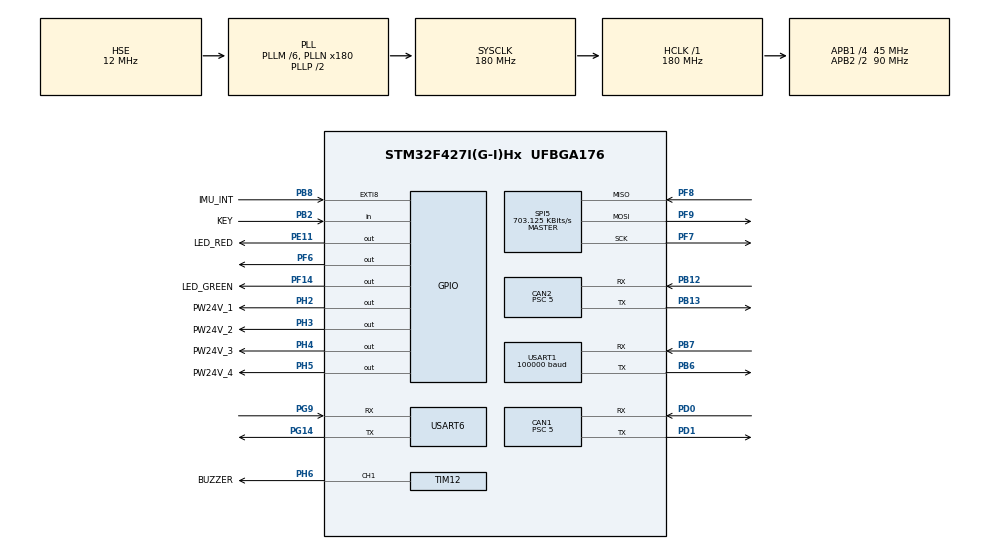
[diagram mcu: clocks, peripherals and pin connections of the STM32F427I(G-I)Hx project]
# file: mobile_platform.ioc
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CAN1.ABOM=ENABLE
CAN1.BS1=CAN_BS1_3TQ
CAN1.BS2=CAN_BS2_5TQ
CAN1.CalculateTimeQuantum=111.11111111111111
CAN1.Prescaler=5
CAN1.TXFP=DISABLE
CAN2.ABOM=ENABLE
CAN2.BS1=CAN_BS1_3TQ
CAN2.BS2=CAN_BS2_5TQ
CAN2.CalculateTimeQuantum=111.11111111111111
CAN2.Prescaler=5
CAN2.TXFP=DISABLE
Dma.Request0=USART1_RX
Dma.USART1_RX.0.Direction=DMA_PERIPH_TO_MEMORY
Dma.USART1_RX.0.FIFOMode=DMA_FIFOMODE_DISABLE
Dma.USART1_RX.0.Instance=DMA2_Stream2
Dma.USART1_RX.0.MemDataAlignment=DMA_MDATAALIGN_BYTE
Dma.USART1_RX.0.MemInc=DMA_MINC_ENABLE
Dma.USART1_RX.0.Mode=DMA_CIRCULAR
Dma.USART1_RX.0.PeriphDataAlignment=DMA_PDATAALIGN_BYTE
Dma.USART1_RX.0.PeriphInc=DMA_PINC_DISABLE
Dma.USART1_RX.0.Priority=DMA_PRIORITY_LOW
FREERTOS.BinarySemaphores01=myBinarySem01,Dynamic,NULL
FREERTOS.INCLUDE_vTaskDelayUntil=1
FREERTOS.Tasks01=defaultTask,0,128,StartDefaultTask,Default,NULL
Mcu.Family=STM32F4
Mcu.Name=STM32F427I(G-I)Hx
Mcu.Package=UFBGA176
NVIC.CAN1_RX0_IRQn=true\:5\:0\:false\:false\:true\:true\:true
NVIC.CAN1_TX_IRQn=true\:5\:0\:false\:false\:true\:true\:true
NVIC.CAN2_RX1_IRQn=true\:5\:0\:false\:false\:true\:true\:true
NVIC.CAN2_TX_IRQn=true\:5\:0\:false\:false\:true\:true\:true
NVIC.DMA2_Stream2_IRQn=true\:5\:0\:false\:false\:true\:true\:false
NVIC.EXTI9_5_IRQn=true\:5\:0\:false\:false\:true\:true\:true
NVIC.PriorityGroup=NVIC_PRIORITYGROUP_4
NVIC.SPI5_IRQn=true\:5\:0\:false\:false\:true\:true\:true
NVIC.USART1_IRQn=true\:5\:0\:false\:false\:true\:true\:true
NVIC.USART6_IRQn=true\:5\:0\:false\:false\:true\:true\:true
PA13.Mode=Serial_Wire
PA13.Signal=SYS_JTMS-SWDIO
PA14.Mode=Serial_Wire
PA14.Signal=SYS_JTCK-SWCLK
PB12.Mode=Slave
PB12.Signal=CAN2_RX
PB13.Mode=Slave
PB13.Signal=CAN2_TX
PB2/BOOT1.GPIO_Label=KEY
PB2/BOOT1.Signal=GPIO_Input
PB6.Mode=Asynchronous
PB6.Signal=USART1_TX
PB7.Mode=Asynchronous
PB7.Signal=USART1_RX
PB8.GPIO_Label=IMU_INT
PB8.Signal=GPXTI8
PD0.Mode=Master
PD0.Signal=CAN1_RX
PD1.Mode=Master
PD1.Signal=CAN1_TX
PE11.GPIO_Label=LED_RED
PE11.Signal=GPIO_Output
PF14.GPIO_Label=LED_GREEN
PF14.Signal=GPIO_Output
PF6.Signal=GPIO_Output
PF7.Mode=Full_Duplex_Master
PF7.Signal=SPI5_SCK
PF8.Mode=Full_Duplex_Master
PF8.Signal=SPI5_MISO
PF9.Mode=Full_Duplex_Master
PF9.Signal=SPI5_MOSI
PG14.Mode=Asynchronous
PG14.Signal=USART6_TX
PG9.Mode=Asynchronous
PG9.Signal=USART6_RX
PH0/OSC_IN.Mode=HSE-External-Oscillator
PH0/OSC_IN.Signal=RCC_OSC_IN
PH1/OSC_OUT.Mode=HSE-External-Oscillator
PH1/OSC_OUT.Signal=RCC_OSC_OUT
PH2.GPIO_Label=PW24V_1
PH2.Signal=GPIO_Output
PH3.GPIO_Label=PW24V_2
PH3.Signal=GPIO_Output
PH4.GPIO_Label=PW24V_3
PH4.Signal=GPIO_Output
PH5.GPIO_Label=PW24V_4
PH5.Signal=GPIO_Output
PH6.GPIO_Label=BUZZER
PH6.Signal=S_TIM12_CH1
ProjectManager.HeapSize=0x500
ProjectManager.StackSize=0x1000
ProjectManager.TargetToolchain=MDK-ARM V5
RCC.48MHZClocksFreq_Value=90000000
RCC.AHBFreq_Value=180000000
RCC.APB1CLKDivider=RCC_HCLK_DIV4
RCC.APB1Freq_Value=45000000
RCC.APB1TimFreq_Value=90000000
RCC.APB2CLKDivider=RCC_HCLK_DIV2
RCC.APB2Freq_Value=90000000
RCC.APB2TimFreq_Value=180000000
RCC.CortexFreq_Value=180000000
RCC.HCLKFreq_Value=180000000
RCC.HSE_VALUE=12000000
RCC.HSI_VALUE=16000000
RCC.LSE_VALUE=32768
RCC.PLLM=6
RCC.PLLN=180
RCC.PLLSourceVirtual=RCC_PLLSOURCE_HSE
RCC.SYSCLKFreq_VALUE=180000000
RCC.SYSCLKSource=RCC_SYSCLKSOURCE_PLLCLK
RCC.VCOOutputFreq_Value=360000000
SH.S_TIM12_CH1.0=TIM12_CH1,PWM Generation1 CH1
SPI5.BaudRatePrescaler=SPI_BAUDRATEPRESCALER_128
SPI5.CalculateBaudRate=703.125 KBits/s
SPI5.Direction=SPI_DIRECTION_2LINES
SPI5.Mode=SPI_MODE_MASTER
SPI5.VirtualType=VM_MASTER
TIM12.Channel-PWM\ Generation1\ CH1=TIM_CHANNEL_1
USART1.BaudRate=100000
USART1.Parity=PARITY_EVEN
USART1.VirtualMode=VM_ASYNC
USART6.VirtualMode=VM_ASYNC
VP_FREERTOS_VS_ENABLE.Mode=Enabled
board=custom

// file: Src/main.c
/**
  ******************************************************************************
  * @file           : main.c
  * @brief          : Main program body
  ******************************************************************************
  * This notice applies to any and all portions of this file
  * that are not between comment pairs USER CODE BEGIN and
  * USER CODE END. Other portions of this file, whether
  * inserted by the user or by software development tools
  * are owned by their respective copyright owners.
  *
  * Copyright (c) 2018 STMicroelectronics International N.V.
  * All rights reserved.
  *
  * Redistribution and use in source and binary forms, with or without
  * modification, are permitted, provided that the following conditions are met:
  *
  * 1. Redistribution of source code must retain the above copyright notice,
  *    this list of conditions and the following disclaimer.
  * 2. Redistributions in binary form must reproduce the above copyright notice,
  *    this list of conditions and the following disclaimer in the documentation
  *    and/or other materials provided with the distribution.
  * 3. Neither the name of STMicroelectronics nor the names of other
  *    contributors to this software may be used to endorse or promote products
  *    derived from this software without specific written permission.
  * 4. This software, including modifications and/or derivative works of this
  *    software, must execute solely and exclusively on microcontroller or
  *    microprocessor devices manufactured by or for STMicroelectronics.
  * 5. Redistribution and use of this software other than as permitted under
  *    this license is void and will automatically terminate your rights under
  *    this license.
  *
  * THIS SOFTWARE IS PROVIDED BY STMICROELECTRONICS AND CONTRIBUTORS "AS IS"
  * AND ANY EXPRESS, IMPLIED OR STATUTORY WARRANTIES, INCLUDING, BUT NOT
  * LIMITED TO, THE IMPLIED WARRANTIES OF MERCHANTABILITY, FITNESS FOR A
  * PARTICULAR PURPOSE AND NON-INFRINGEMENT OF THIRD PARTY INTELLECTUAL PROPERTY
  * RIGHTS ARE DISCLAIMED TO THE FULLEST EXTENT PERMITTED BY LAW. IN NO EVENT
  * SHALL STMICROELECTRONICS OR CONTRIBUTORS BE LIABLE FOR ANY DIRECT, INDIRECT,
  * INCIDENTAL, SPECIAL, EXEMPLARY, OR CONSEQUENTIAL DAMAGES (INCLUDING, BUT NOT
  * LIMITED TO, PROCUREMENT OF SUBSTITUTE GOODS OR SERVICES; LOSS OF USE, DATA,
  * OR PROFITS; OR BUSINESS INTERRUPTION) HOWEVER CAUSED AND ON ANY THEORY OF
  * LIABILITY, WHETHER IN CONTRACT, STRICT LIABILITY, OR TORT (INCLUDING
  * NEGLIGENCE OR OTHERWISE) ARISING IN ANY WAY OUT OF THE USE OF THIS SOFTWARE,
  * EVEN IF ADVISED OF THE POSSIBILITY OF SUCH DAMAGE.
  *
  ******************************************************************************
  */
#include "main.h"
#include "stm32f4xx_hal.h"
#include "cmsis_os.h"
#include "can.h"
#include "dma.h"
#include "spi.h"
#include "tim.h"
#include "usart.h"
#include "gpio.h"

/* USER CODE BEGIN Includes */
#include "sys_config.h"
/* USER CODE END Includes */

/* USER CODE BEGIN PV */
/* Private variables ---------------------------------------------------------*/

/* USER CODE END PV */

void SystemClock_Config(void);
void MX_FREERTOS_Init(void);

/* USER CODE BEGIN PFP */
/* Private function prototypes -----------------------------------------------*/

/* USER CODE END PFP */

int main(void)
{

  /* MCU Configuration----------------------------------------------------------*/

  /* Reset of all peripherals, Initializes the Flash interface and the Systick. */
  HAL_Init();

  /* Configure the system clock */
  SystemClock_Config();

  /* Initialize all configured peripherals */
  MX_GPIO_Init();
  MX_DMA_Init();
  MX_USART1_UART_Init();
  MX_USART6_UART_Init();
  MX_CAN1_Init();
  MX_CAN2_Init();
  MX_TIM12_Init();
  MX_SPI5_Init();
  /* USER CODE BEGIN 2 */
//  delay_init(180);
	HAL_TIM_PWM_Start(&htim12,TIM_CHANNEL_1);
	led_off();
	dbus_uart_init();
	can_filter_init(&hcan1);
	can_filter_init(&hcan2);
  /* USER CODE END 2 */

  /* Call init function for freertos objects (in freertos.c) */
  MX_FREERTOS_Init();

  /* Start scheduler */
  osKernelStart();

  /* We should never get here as control is now taken by the scheduler */

  /* Infinite loop */
  while (1)
  {

  }

}

void SystemClock_Config(void)
{

  RCC_OscInitTypeDef RCC_OscInitStruct;
  RCC_ClkInitTypeDef RCC_ClkInitStruct;

    /**Configure the main internal regulator output voltage
    */
  __HAL_RCC_PWR_CLK_ENABLE();

  __HAL_PWR_VOLTAGESCALING_CONFIG(PWR_REGULATOR_VOLTAGE_SCALE1);

    /**Initializes the CPU, AHB and APB busses clocks
    */
  RCC_OscInitStruct.OscillatorType = RCC_OSCILLATORTYPE_HSE;
  RCC_OscInitStruct.HSEState = RCC_HSE_ON;
  RCC_OscInitStruct.PLL.PLLState = RCC_PLL_ON;
  RCC_OscInitStruct.PLL.PLLSource = RCC_PLLSOURCE_HSE;
  RCC_OscInitStruct.PLL.PLLM = 6;
  RCC_OscInitStruct.PLL.PLLN = 180;
  RCC_OscInitStruct.PLL.PLLP = RCC_PLLP_DIV2;
  RCC_OscInitStruct.PLL.PLLQ = 4;
  if (HAL_RCC_OscConfig(&RCC_OscInitStruct) != HAL_OK)
  {
    _Error_Handler(__FILE__, __LINE__);
  }

    /**Activate the Over-Drive mode
    */
  if (HAL_PWREx_EnableOverDrive() != HAL_OK)
  {
    _Error_Handler(__FILE__, __LINE__);
  }

    /**Initializes the CPU, AHB and APB busses clocks
    */
  RCC_ClkInitStruct.ClockType = RCC_CLOCKTYPE_HCLK|RCC_CLOCKTYPE_SYSCLK
                              |RCC_CLOCKTYPE_PCLK1|RCC_CLOCKTYPE_PCLK2;
  RCC_ClkInitStruct.SYSCLKSource = RCC_SYSCLKSOURCE_PLLCLK;
  RCC_ClkInitStruct.AHBCLKDivider = RCC_SYSCLK_DIV1;
  RCC_ClkInitStruct.APB1CLKDivider = RCC_HCLK_DIV4;
  RCC_ClkInitStruct.APB2CLKDivider = RCC_HCLK_DIV2;

  if (HAL_RCC_ClockConfig(&RCC_ClkInitStruct, FLASH_LATENCY_5) != HAL_OK)
  {
    _Error_Handler(__FILE__, __LINE__);
  }

    /**Configure the Systick interrupt time
    */
  HAL_SYSTICK_Config(HAL_RCC_GetHCLKFreq()/1000);

    /**Configure the Systick
    */
  HAL_SYSTICK_CLKSourceConfig(SYSTICK_CLKSOURCE_HCLK);

  /* SysTick_IRQn interrupt configuration */
  HAL_NVIC_SetPriority(SysTick_IRQn, 15, 0);
}

void _Error_Handler(char *file, int line)
{
  while(1)
  {
  }
}

/************************ (C) COPYRIGHT STMicroelectronics *****END OF FILE****/

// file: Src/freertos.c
/* USER CODE BEGIN Header */
/**
  ******************************************************************************
  * File Name          : freertos.c
  * Description        : Code for freertos applications
  ******************************************************************************
  * This notice applies to any and all portions of this file
  * that are not between comment pairs USER CODE BEGIN and
  * USER CODE END. Other portions of this file, whether
  * inserted by the user or by software development tools
  * are owned by their respective copyright owners.
  *
  * Copyright (c) 2018 STMicroelectronics International N.V.
  * All rights reserved.
  *
  * Redistribution and use in source and binary forms, with or without
  * modification, are permitted, provided that the following conditions are met:
  *
  * 1. Redistribution of source code must retain the above copyright notice,
  *    this list of conditions and the following disclaimer.
  * 2. Redistributions in binary form must reproduce the above copyright notice,
  *    this list of conditions and the following disclaimer in the documentation
  *    and/or other materials provided with the distribution.
  * 3. Neither the name of STMicroelectronics nor the names of other
  *    contributors to this software may be used to endorse or promote products
  *    derived from this software without specific written permission.
  * 4. This software, including modifications and/or derivative works of this
  *    software, must execute solely and exclusively on microcontroller or
  *    microprocessor devices manufactured by or for STMicroelectronics.
  * 5. Redistribution and use of this software other than as permitted under
  *    this license is void and will automatically terminate your rights under
  *    this license.
  *
  * THIS SOFTWARE IS PROVIDED BY STMICROELECTRONICS AND CONTRIBUTORS "AS IS"
  * AND ANY EXPRESS, IMPLIED OR STATUTORY WARRANTIES, INCLUDING, BUT NOT
  * LIMITED TO, THE IMPLIED WARRANTIES OF MERCHANTABILITY, FITNESS FOR A
  * PARTICULAR PURPOSE AND NON-INFRINGEMENT OF THIRD PARTY INTELLECTUAL PROPERTY
  * RIGHTS ARE DISCLAIMED TO THE FULLEST EXTENT PERMITTED BY LAW. IN NO EVENT
  * SHALL STMICROELECTRONICS OR CONTRIBUTORS BE LIABLE FOR ANY DIRECT, INDIRECT,
  * INCIDENTAL, SPECIAL, EXEMPLARY, OR CONSEQUENTIAL DAMAGES (INCLUDING, BUT NOT
  * LIMITED TO, PROCUREMENT OF SUBSTITUTE GOODS OR SERVICES; LOSS OF USE, DATA,
  * OR PROFITS; OR BUSINESS INTERRUPTION) HOWEVER CAUSED AND ON ANY THEORY OF
  * LIABILITY, WHETHER IN CONTRACT, STRICT LIABILITY, OR TORT (INCLUDING
  * NEGLIGENCE OR OTHERWISE) ARISING IN ANY WAY OUT OF THE USE OF THIS SOFTWARE,
  * EVEN IF ADVISED OF THE POSSIBILITY OF SUCH DAMAGE.
  *
  ******************************************************************************
  */
/* USER CODE END Header */

#include "FreeRTOS.h"
#include "task.h"
#include "main.h"
#include "cmsis_os.h"

/* USER CODE BEGIN Includes */
#include "sys_config.h"
/* USER CODE END Includes */

/* USER CODE BEGIN Variables */
osThreadId chassis_ctrl_TaskHandle;
/* USER CODE END Variables */
osThreadId defaultTaskHandle;
osSemaphoreId myBinarySem01Handle;

void StartDefaultTask(void const * argument);

void MX_FREERTOS_Init(void); /* (MISRA C 2004 rule 8.1) */

void MX_FREERTOS_Init(void) {

  /* Create the semaphores(s) */
  /* definition and creation of myBinarySem01 */
  osSemaphoreDef(myBinarySem01);
  myBinarySem01Handle = osSemaphoreCreate(osSemaphore(myBinarySem01), 1);

  /* Create the thread(s) */
  /* definition and creation of defaultTask */
  osThreadDef(defaultTask, StartDefaultTask, osPriorityNormal, 0, 128);
  defaultTaskHandle = osThreadCreate(osThread(defaultTask), NULL);

  /* USER CODE BEGIN RTOS_THREADS */
  /* add threads, ... */
  osThreadDef(chassis_ctrl_task, Start_chassis_ctrl_task, osPriorityNormal, 0, 128);
  chassis_ctrl_TaskHandle = osThreadCreate(osThread(chassis_ctrl_task), NULL);
  /* USER CODE END RTOS_THREADS */

}

void StartDefaultTask(void const * argument)
{

  /* USER CODE BEGIN StartDefaultTask */
  /* Infinite loop */
  for(;;)
  {
    led_blink(1);
    osDelay(1);
  }
  /* USER CODE END StartDefaultTask */
}

/************************ (C) COPYRIGHT STMicroelectronics *****END OF FILE****/
